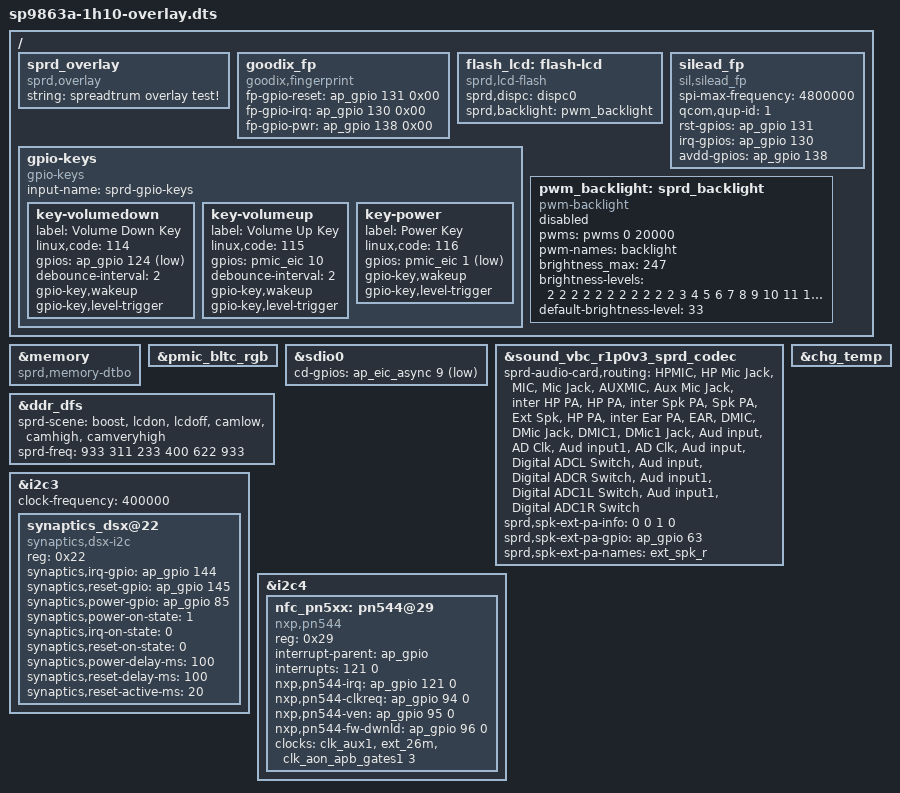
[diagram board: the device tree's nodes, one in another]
/*
 * Spreadtrum sharkl3 sp9863a board DTS file
 *
 * Copyright (C) 2018, Spreadtrum Communications Inc.
 *
 * This file is licensed under a dual GPLv2 or X11 license.
 */
/dts-v1/;
/plugin/;

/ {
	/*
	* When create a new node, we should use the key word __overlay__,
	* otherwise u-boot can not analyze it.
	*/

	fragment {
		target-path = "/";
		__overlay__ {
			sprd_overlay {
				compatible = "sprd,overlay";
				string = "spreadtrum overlay test!";
			};
			goodix_fp{
				compatible = "goodix,fingerprint";
				fp-gpio-reset = <&ap_gpio 131 0x00>;
				fp-gpio-irq = <&ap_gpio 130 0x00>;
				fp-gpio-pwr = <&ap_gpio 138 0x00>;
			};
			flash_lcd: flash-lcd {
				compatible = "sprd,lcd-flash";
				sprd,dispc = <&dispc0>;
				sprd,backlight = <&pwm_backlight>;
				status = "okay";
			};
			silead_fp {
				compatible = "sil,silead_fp";
				spi-max-frequency = <4800000>;
				qcom,qup-id = <1>;
				rst-gpios = <&ap_gpio 131 0x00>;
				irq-gpios = <&ap_gpio 130 0x00>;
				avdd-gpios = <&ap_gpio 138 0x00>;
			};
			gpio-keys {
				compatible = "gpio-keys";
				input-name = "sprd-gpio-keys";
				status = "okay";

				key-volumedown {
					label = "Volume Down Key";
					linux,code = <114>;
					gpios = <&ap_gpio 124 1>;
					debounce-interval = <2>;
					gpio-key,wakeup;
					gpio-key,level-trigger;
				};

				key-volumeup {
					label = "Volume Up Key";
					linux,code = <115>;
					gpios = <&pmic_eic 10 0>;
					debounce-interval = <2>;
					gpio-key,wakeup;
					gpio-key,level-trigger;
				};

				key-power {
					label = "Power Key";
					linux,code = <116>;
					gpios = <&pmic_eic 1 1>;
					gpio-key,wakeup;
					gpio-key,level-trigger;
				};
			};

			pwm_backlight: sprd_backlight {
				compatible = "pwm-backlight";
				pwms = <&pwms 0 20000>;
				pwm-names = "backlight";
				brightness_max = <247>;
				brightness-levels = <
						  2   2   2   2   2   2   2   2
					  2   2   2   3   4   5   6   7   8   9
					 10  11  12  13  14  15  16  17  18  19
					 20  21  22  23  24  25  26  27  28  29
					 30  31  32  33  34  35  36  37  38  39
					 40  41  42  43  44  45  46  47  48  49
					 50  51  52  53  54  55  56  57  58  59
					 60  61  62  63  64  65  66  67  68  69
					 70  71  72  73  74  75  76  77  78  79
					 80  81  82  83  84  85  86  87  88  89
					 90  91  92  93  94  95  96  97  98  99
					100 101 102 103 104 105 106 107 108 109
					110 111 112 113 114 115 116 117 118 119
					120 121 122 123 124 125 126 127 128 129
					130 131 132 133 134 135 136 137 138 139
					140 141 142 143 144 145 146 147 148 149
					150 151 152 153 154 155 156 157 158 159
					160 161 162 163 164 165 166 167 168 169
					170 171 172 173 174 175 176 177 178 179
					180 181 182 183 184 185 186 187 188 189
					190 191 192 193 194 195 196 197 198 199
					200 201 202 203 204 205 206 207 208 209
					210 211 212 213 214 215 216 217 218 219
					220 221 222 223 224 225 226 227 228 229
					230 231 232 233 234 235 236 237 238 239
					240 241 242 243 244 245 246 247
					>;
				default-brightness-level = <33>;
			};
		};
	};
};

/*
 * Sample code. Google strongly recommends you do not use fragment@x and
 * syntax __overlay__, and instead use the reference syntax
 */
&memory {
	compatible = "sprd,memory-dtbo";
};

&pwm_backlight {
	status = "disabled";
};
&pmic_bltc_rgb {
	status = "okay";
};

&sdio0 {
	cd-gpios =<&ap_eic_async 9 1>;
	/delete-property/ sd-uhs-sdr104;
};

&sound_vbc_r1p0v3_sprd_codec {
	sprd-audio-card,routing =
		"HPMIC", "HP Mic Jack",
		"MIC", "Mic Jack",
		"AUXMIC", "Aux Mic Jack",
		"inter HP PA", "HP PA",
		"inter Spk PA", "Spk PA",
		"Ext Spk", "HP PA",
		"inter Ear PA", "EAR",
		"DMIC", "DMic Jack",
		"DMIC1", "DMic1 Jack",

		/* For vbc loopback */
		"Aud input", "AD Clk",
		"Aud input1", "AD Clk",
		"Aud input", "Digital ADCL Switch",
		"Aud input", "Digital ADCR Switch",
		"Aud input1", "Digital ADC1L Switch",
		"Aud input1", "Digital ADC1R Switch";
	/* ext_control_type, hook selection, mode, gpio share */
	sprd,spk-ext-pa-info = <0 0 1 0>;
	sprd,spk-ext-pa-gpio = <&ap_gpio 63 0>;
	sprd,spk-ext-pa-names = "ext_spk_r";
};
&ddr_dfs {
	sprd-scene = "boost", "lcdon", "lcdoff", "camlow",
			"camhigh", "camveryhigh";
	sprd-freq = <933 311 233 400 622 933>;
};

&chg_temp {
	status = "okay";
};
&i2c3 {
	status = "okay";
	clock-frequency = <400000>;
	synaptics_dsx@22 {
		compatible = "synaptics,dsx-i2c";
		reg = <0x22>;
		synaptics,irq-gpio = <&ap_gpio 144 0x2008>;
		synaptics,reset-gpio = <&ap_gpio 145 0>;
		synaptics,power-gpio = <&ap_gpio 85 0>;
		synaptics,power-on-state = <1>;
		synaptics,irq-on-state = <0>;
		synaptics,reset-on-state = <0>;
		synaptics,power-delay-ms = <100>;
		synaptics,reset-delay-ms = <100>;
		synaptics,reset-active-ms = <20>;
	};
};

&i2c4 {
	nfc_pn5xx: pn544@29 {
		compatible = "nxp,pn544";
		reg = <0x29>;
		interrupt-parent = <&ap_gpio>;
		interrupts = <121 0>;
		nxp,pn544-irq = <&ap_gpio 121 0>;
		nxp,pn544-clkreq = <&ap_gpio 94 0>;
		nxp,pn544-ven = <&ap_gpio 95 0>;
		nxp,pn544-fw-dwnld = <&ap_gpio 96 0>;
		interrupt-names = "nfc_int";
		clock-names = "bb_clk2","source","enable";
		clocks = <&clk_aux1>,<&ext_26m>,<&clk_aon_apb_gates1 3>;
	};
};
